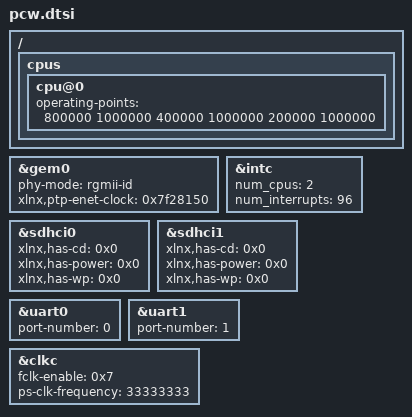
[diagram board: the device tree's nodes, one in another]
/*
 * CAUTION: This file is automatically generated by Xilinx.
 * Version:  
 * Today is: Tue Jan 21 17:48:53 2020
 */


/ {
	cpus {
		cpu@0 {
			operating-points = <800000 1000000 400000 1000000 200000 1000000>;
		};
	};
};
&gem0 {
	phy-mode = "rgmii-id";
	status = "okay";
	xlnx,ptp-enet-clock = <0x7f28150>;
};
&intc {
	num_cpus = <2>;
	num_interrupts = <96>;
};
&sdhci0 {
	status = "okay";
	xlnx,has-cd = <0x0>;
	xlnx,has-power = <0x0>;
	xlnx,has-wp = <0x0>;
};
&sdhci1 {
	status = "okay";
	xlnx,has-cd = <0x0>;
	xlnx,has-power = <0x0>;
	xlnx,has-wp = <0x0>;
};
&uart0 {
	device_type = "serial";
	port-number = <0>;
	status = "okay";
};
&uart1 {
	device_type = "serial";
	port-number = <1>;
	status = "okay";
};
&clkc {
	fclk-enable = <0x7>;
	ps-clk-frequency = <33333333>;
};
